# YTM32B1MD2 register map
Vendor: YTMicro; File version: 1.0
CPU: CM33 r0p4, little endian, MPU, FPU, 2 interrupt priority bits
Registers are 32-bit, read-write, reset 0x0 unless marked. A register's access mark holds for its fields unless they carry their own. Offsets are from the block's base; [hi:lo] are bit positions; {n}, {i} and the like mark numbered series; 'fields as' and 'values as' point back to an identical list.

## eADC0 — Enhanced Analog-to-Digital Converter
Base 0x40040000; register names take the prefix eADC0_
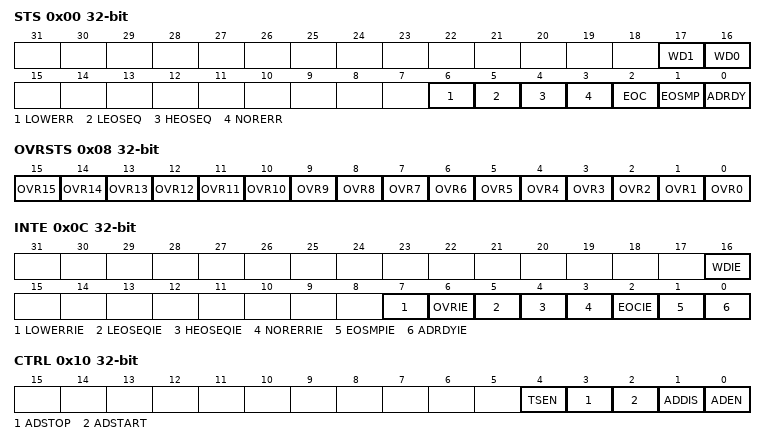
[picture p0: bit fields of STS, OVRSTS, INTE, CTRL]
0x00 STS
  [17] WD1 — This bit is set by hardware when the converted voltage crosses the values defined in the WD1TH register. It is cleared by software writing 1 to it.
    0=No watchdog event occurred (or the flag event was already acknowledged and cleared by software); 1=Watchdog event occurred
  [16] WD0 — This bit is set by hardware when the converted voltage crosses the values defined in the WD0TH register. It is cleared by software writing 1 to it.
    values as WD1
  [6] LOWERR — This bit is set by low priority sequence hardware when low priority sequence hardware trigger error occurs. Low priority trigger error occurs when the low priority sequcence conversion is in process and a new low priority hardware trigger comes. It is cleared by software writing 1 to it.
    0=Indicate low priority hardware trigger not missing; 1=Indicate low priority hardware trigger missing
  [5] LEOSEQ — This bit is set by hardware at the end of low-priority sequence. Ir is cleared by software writing 1 to it.
    0=Low-priority sequence not complete (or the flag event was already acknowledged and cleared by software); 1=Low-priority sequence complete
  [4] HEOSEQ — This bit is set by hardware at the end of high-priority sequence. Ir is cleared by software writing 1 to it.
    0=High-priority sequence not complete (or the flag event was already acknowledged and cleared by software); 1=High-priority sequence complete
  [3] NORERR — This bit is set by hardware when hardware trigger error occurs. Normal trigger error occurs when the high-priority sequence conversion is in progress and a new hardware trigger comes. It is cleared by software writing 1 to it.
    0=Indicate high-priority sequence hardware trigger not missing; 1=Indicate high-priority sequence hardware trigger missing
  [2] EOC — This bit is set by hardware at the end of each conversion of a channel when a new data result is available in the DATA register. It is cleared by software writing 1 to it or by reading any DATA register.
    0=Channel conversion not complete (or the flag event was already acknowledged and cleared by software); 1=Channel conversion complete
  [1] EOSMP — This bit is set by hardware during the conversion at the end of the sampling phase.
    0=Not at the end of the sampling phase (or the flag event was already acknowledged and cleared by software); 1=End of sampling phase reached
  [0] ADRDY — This bit is set by hardware after the eADC has been enabled (ADEN=1) and when the eADC reaches a state where it is ready to accept conversion requests. It is cleared by software writing 1 to it.
    0=eADC not yet ready to start conversion (or the flag event was already acknowledged and cleared by software); 1=eADC is ready to start conversion
0x08 OVRSTS
  [n] OVR{n} (n=0..15) — Indicate data {n} register is override. It is cleared by software writing 1 to it.
0x0C INTE
  [16] WDIE — This bit is set and cleared by software to enable/disable the analog watchdog interrupt.
    0=Watchdog interrupt disabled; 1=Watchdog interrupt enabled. An interrupt is generated when any WD bit is set.
  [7] LOWERRIE — Low priority trigger error interrupt enable/disabled.
    0=Low priority trigger error interrupt disabled; 1=Low priority trigger error interrupt enabled
  [6] OVRIE — This bit is set and cleared by software to enable/disable the overrun interrupt.
    0=Overrun interrupt disabled; 1=Overrun interrupt enabled. An interrupt is generated when the OVR bit is set.
  [5] LEOSEQIE — This bit is set and cleared by software to enable/disable the low-priority end of sequence of conversions interrupt.
    0=LEOSEQ interrupt disabled; 1=LEOSEQ interrupt enabled. An interrupt is generated when the LEOSEQ bit is set.
  [4] HEOSEQIE — This bit is set and cleared by software to enable/disable the high-priority Sequence end of conversions interrupt.
    0=HEOSEQ interrupt disabled; 1=HEOSEQ interrupt enabled. An interrupt is generated when the HEOSEQ bit is set.
  [3] NORERRIE — Normal error interrupt enabled/disabled.
    0=Normal error interrupt disabled; 1=Normal error interrupt enabled
  [2] EOCIE — This bit is set and cleared by software to enable/disable the end of conversion interrupt.
    0=EOC interrupt disabled; 1=EOC interrupt enabled. An interrupt is generated when the EOC bit is set.
  [1] EOSMPIE — This bit is set and cleared by software to enable/disable the end of the sampling phase interrupt.
    0=EOSMP interrupt disabled; 1=EOSMP interrupt enabled. An interrupt is generated when the EOSMP bit is set.
  [0] ADRDYIE — This bit is set and cleared by software to enable/disable the eADC Ready interrupt.
    0=ADRDY interrupt disabled; 1=ADRDY interrupt enabled. An interrupt is generated when the ADRDY bit is set.
0x10 CTRL
  [4] TSEN — This bit is to enable/disable internal temperature sensor.
    0=Temperature sensor is disabled; 1=Temperature sensor is enabled
  [3] ADSTOP — This bit is set by software to stop and discard an ongoing conversion (ADSTOP Command). It is cleared by hardware when the conversion is effectively discarded and the eADC is ready to accept a new start conversion command. Software is allowed to set ADSTOP only when ADSTART=1 and ADDIS=0 (eADC is enabled and may be converting and there is no pending request to disable the eADC).
    0=No eADC stop conversion command ongoing; 1=Write 1 to stop the eADC. Read 1 means that an ADSTOP command is in progress.
  [2] ADSTART — This bit is set by software to start eADC conversion. Depending on the NORTMD configuration bits, conversion either starts immediately (software trigger configuration) or once a hardware trigger event occurs (hardware trigger configuration). Software is allowed to set ADSTART only when ADEN=1 and ADDIS=0 (eADC is enabled and there is no pending request to disable the eADC).
    0=No eADC software sequence conversion is ongoing; 1=Write 1 to start the eADC. Read 1 means that the eADC is operating and may be converting.
  [1] ADDIS — This bit is set by software to disable the eADC (ADDIS command) and put it into power-down state (OFF state). It is cleared by hardware once the eADC is effectively disabled (ADEN is also cleared by hardware at this time).
    0=No ADDIS command ongoing; 1=Write 1 to disable the eADC. Read 1 means that an ADDIS command is in progress.
  [0] ADEN — This bit is set by software to enable the eADC. The eADC will be effectively ready to operate once the ADRDY flag has been set. It is cleared by hardware when the eADC is disabled, after the execution of the ADDIS command.
    0=eADC is disabled (OFF state); 1=Write 1 to enable the eADC. Read 1 means that the eADC is enabled.
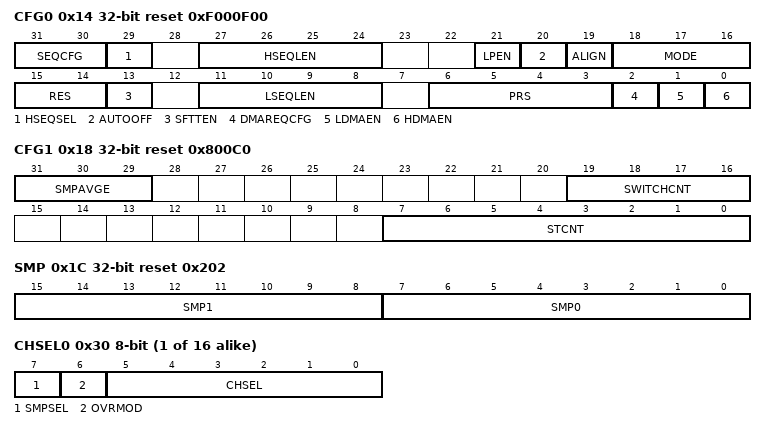
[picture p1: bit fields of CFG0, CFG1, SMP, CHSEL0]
0x14 CFG0 reset 0xF000F00
  [31:30] SEQCFG — These bit used to config hardware sequence and software sequence capacity
    0=seq0 length is 15, seq1 length is 1; 1=seq0 length is 2, seq1 length is 14; 2=seq0 length is 4, seq1 length is 12; 3=seq0 length is 8, seq1 length is 8
  [29] HSEQSEL — This bit used to Select which sequence capacity as high-priority sequence capacity
    0=seq0 as high-priority sequence, seq1 as low-priority sequence; 1=seq1 as high-priority sequence, seq0 as low-priority sequence
  [27:24] HSEQLEN — These bits define the length of high-priority sequence. The sequence length is HSEQLEN+1. For example, HSEQLEN=7 means sequence length is 8; HSEQLEN=0 means sequence length is 1. The max capacity is due to SEQCFG and HSEQSEL
  [21] LPEN — Keep working enabled/disabled in low power mode. Please clear this bit when in standby mode for power saving.
    0=Keep working disabled in low power mode; 1=Keep working enabled in low power mode
  [20] AUTOOFF — This bit is set and cleared by software to enable/disable auto-off mode.
    0=Auto-off mode disabled; 1=Auto-off mode enabled
  [19] ALIGN — Data right/left aligned when read DATA register.
    0=Right aligned; 1=Left aligned
  [18:16] MODE — Work mode selection.
    0=High-priority sequence is in single mode, Low-priority sequence is in single mode; 1=High-priority sequence is in single mode, Low-priority sequence is in continuous mode; 2=High-priority sequence is in single mode, Low-priority sequence is in discontinuous mode; 3=High-priority sequence is in discontinuous mode, Low-priority sequence is in single mode; 4=High-priority sequence is in continuous mode, Low-priority sequence is in single mode; 5=High-priority sequence is in discontinuous mode, Low-priority sequence is in discontinuous mode; 6=High-priority sequence is in continuous mode, Low-priority sequence is in discontinuous mode; 7=High-priority sequence is in discontinuous mode, Low-priority sequence is in continuous mode
  [15:14] RES — These bits are written by software to select the resolution of the conversion.
    0=12-bit resolution; 1=10-bit resolution; 2=8-bit resolution; 3=6-bit resolution
  [13] SFTTEN — The bit is used to select low-priority sequence use software trigger or hardware trigger.
    0=Enable low-priority sequence hardware trigger; 1=Enable low-priority sequence software trigger
  [11:8] LSEQLEN — These bits define the length of low-priority sequence. The sequence length is LSEQLEN+1. For example, LSEQLEN=7 means sequence length is 8; LSEQLEN=0 means sequence length is 1. The max capacity is due to SEQCFG and HSEQSEL
  [6:3] PRS
  [2] DMAREQCFG — This bit is set and cleared by software to configuration whether generate dma request when override events occur.
    0=Dma request generates don't care about override events; 1=No dma request is generated if an override event is generated in the conversion sequence
  [1] LDMAEN — This bit is set and cleared by software to enable the generation of Low-priority sequence DMA requests. This allows to use the DMA controller to manage conversion data automatically.
  [0] HDMAEN — This bit is set and cleared by software to enable the generation of High-priority sequence DMA requests. This allows to use the DMA controller to manage conversion data automatically.
0x18 CFG1 reset 0x800C0
  [31:29] SMPAVGE — These bit definitions are averaged over several samples to get an average result.
    0=No sample averaging; 1=The results of the 2 conversions are averaged; 2=The results of the 4 conversions are averaged; 3=The results of the 8 conversions are averaged; 4=The results of the 16 conversions are averaged; 5=The results of the 32 conversions are averaged
  [19:16] SWITCHCNT
  [7:0] STCNT
0x1C SMP reset 0x202
  [15:8] SMP1, [7:0] SMP0
{0x30+i} CHSEL{i} 8-bit (i=0..15)
  [7] SMPSEL — This bit is used to select which SMP in current channel
    0=Select SMP0 as current channel sampling time; 1=Select SMP1 as current channel sampling time
  [6] OVRMOD — This bit is used to select whether allowed cover current channel converse data when override occur
    0=Allowed cover current channel converse data when override event occur; 1=Keeping original data from being overwritten
  [5:0] CHSEL — These bits are configured by software to select the conversion channel.
0x54 TSC
  [11:0] COEFF — Temperature sensor coefficient value, this register bit is reset by System Reset.
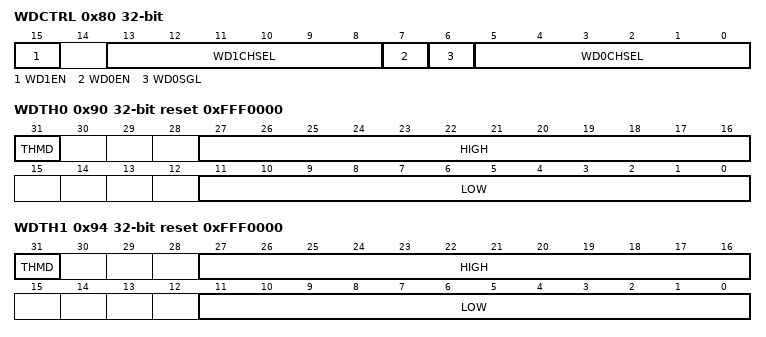
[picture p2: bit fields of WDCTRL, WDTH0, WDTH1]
0x80 WDCTRL
  [15] WD1EN — This bit is set and cleared by software to enable/disable watchdog.
    0=Watchdog 1 is disabled; 1=Watchdog 1 is enabled
  [13:8] WD1CHSEL — These bits are set and cleared by software. They select the input channel to be guarded by the watchdog.
  [7] WD0EN — This bit is set and cleared by software to enable/disable watchdog.
    0=Watchdog 0 is disabled; 1=Watchdog 0 is enabled
  [6] WD0SGL — This bit is set and cleared by software to apply the watchdog on the channel identified by the WDCHSEL or all channels.
    0=Watchdog 0 enabled on all channels; 1=Watchdog 0 enabled on a single channel
  [5:0] WD0CHSEL — These bits are set and cleared by software. They select the input channel to be guarded by the watchdog.
0x90 WDTH0 reset 0xFFF0000
  [31] THMD — This bit is set and cleared by software to select the watchdog 0 threshold effective mode.
    0=Watchdog output validly when the converted voltage is outside the threshold defined by HIGH and LOW; 1=Watchdog output validly when the converted voltage is inside the threshold defined by HIGH and LOW
  [27:16] HIGH — These bits are written by software to define the higher threshold for the watchdog 0.
  [11:0] LOW — These bits are written by software to define the lower threshold for the watchdog 0.
0x94 WDTH1 reset 0xFFF0000
  fields as WDTH0
{0xD0+4i} DATA{i} (i=0..15)
  [15:0] DB — These bits contain the conversion results of the eADC's corresponding sequence channels.
